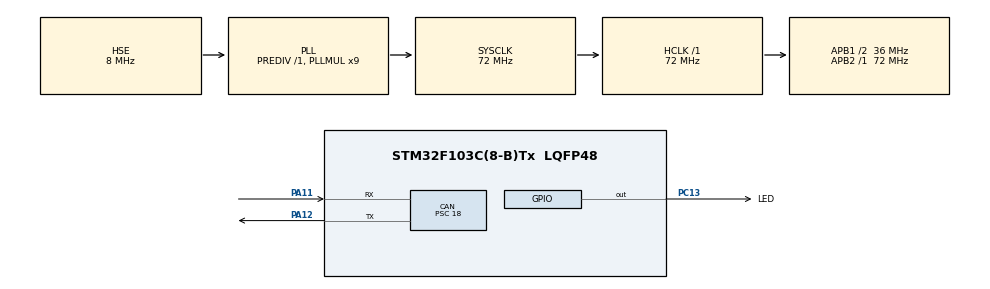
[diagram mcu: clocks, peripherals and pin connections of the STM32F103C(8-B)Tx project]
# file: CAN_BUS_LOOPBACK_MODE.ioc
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CAN.BS1=CAN_BS1_2TQ
CAN.CalculateBaudRate=500000
CAN.CalculateTimeBit=2000
CAN.CalculateTimeQuantum=500.0
CAN.Mode=CAN_MODE_LOOPBACK
CAN.Prescaler=18
CAN.SJW=CAN_SJW_1TQ
Mcu.Family=STM32F1
Mcu.Name=STM32F103C(8-B)Tx
Mcu.Package=LQFP48
NVIC.CAN1_RX1_IRQn=true\:0\:0\:false\:false\:true\:true\:true
NVIC.PriorityGroup=NVIC_PRIORITYGROUP_4
NVIC.USB_LP_CAN1_RX0_IRQn=true\:0\:0\:true\:false\:true\:true\:true
PA11.Mode=CAN_Activate
PA11.Signal=CAN_RX
PA12.Mode=CAN_Activate
PA12.Signal=CAN_TX
PA13.Mode=Serial_Wire
PA13.Signal=SYS_JTMS-SWDIO
PA14.Mode=Serial_Wire
PA14.Signal=SYS_JTCK-SWCLK
PC13-TAMPER-RTC.GPIO_Label=LED
PC13-TAMPER-RTC.PinState=GPIO_PIN_SET
PC13-TAMPER-RTC.Signal=GPIO_Output
PD0-OSC_IN.Mode=HSE-External-Oscillator
PD0-OSC_IN.Signal=RCC_OSC_IN
PD1-OSC_OUT.Mode=HSE-External-Oscillator
PD1-OSC_OUT.Signal=RCC_OSC_OUT
ProjectManager.HeapSize=0x200
ProjectManager.StackSize=0x400
ProjectManager.TargetToolchain=STM32CubeIDE
RCC.AHBFreq_Value=72000000
RCC.APB1CLKDivider=RCC_HCLK_DIV2
RCC.APB1Freq_Value=36000000
RCC.APB1TimFreq_Value=72000000
RCC.APB2Freq_Value=72000000
RCC.APB2TimFreq_Value=72000000
RCC.HCLKFreq_Value=72000000
RCC.PLLMUL=RCC_PLL_MUL9
RCC.PLLSourceVirtual=RCC_PLLSOURCE_HSE
RCC.SYSCLKFreq_VALUE=72000000
RCC.SYSCLKSource=RCC_SYSCLKSOURCE_PLLCLK
RCC.USBFreq_Value=72000000
board=custom

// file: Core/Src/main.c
/* USER CODE BEGIN Header */
/**
  ******************************************************************************
  * @file           : main.c
  * @brief          : Main program body
  ******************************************************************************
  * @attention
  *
  * Copyright (c) 2022 STMicroelectronics.
  * All rights reserved.
  *
  * This software is licensed under terms that can be found in the LICENSE file
  * in the root directory of this software component.
  * If no LICENSE file comes with this software, it is provided AS-IS.
  *
  ******************************************************************************
  */
/* USER CODE END Header */
#include "main.h"

CAN_HandleTypeDef hcan;

/* USER CODE BEGIN PV */
CAN_TxHeaderTypeDef TxHeader;
CAN_RxHeaderTypeDef RxHeader;

uint8_t				TxData[8];
uint8_t				RxData[8];

uint32_t			TxMailbox[4];
uint8_t				count = 0;

uint32_t			last_time = 0;
/* USER CODE END PV */

void SystemClock_Config(void);
static void MX_GPIO_Init(void);
static void MX_CAN_Init(void);

/* USER CODE BEGIN 0 */
void HAL_CAN_RxFifo0MsgPendingCallback(CAN_HandleTypeDef *hcan)
{
	HAL_CAN_GetRxMessage(hcan, CAN_RX_FIFO0, &RxHeader, RxData);
	//HAL_GPIO_TogglePin(GPIOC, GPIO_PIN_13);
	count++;
}

void HAL_GPIO_EXTI_Callback(uint16_t GPIO_PIN)
{
	/*
	if (GPIO_PIN == GPIO_PIN_0)
	{
		if (HAL_GetTick() - last_time >= 200)
		{
			last_time = HAL_GetTick();
			count++;
			TxData[0] = count;
			HAL_CAN_AddTxMessage(&hcan, &TxHeader, TxData, &TxMailbox);
		}

	}
	*/
}

/* USER CODE END 0 */

int main(void)
{

  /* MCU Configuration--------------------------------------------------------*/

  /* Reset of all peripherals, Initializes the Flash interface and the Systick. */
  HAL_Init();

  /* Configure the system clock */
  SystemClock_Config();

  /* Initialize all configured peripherals */
  MX_GPIO_Init();
  MX_CAN_Init();
  /* USER CODE BEGIN 2 */

  HAL_CAN_Start(&hcan);

  HAL_CAN_ActivateNotification(&hcan, CAN_IT_RX_FIFO0_MSG_PENDING);

  TxHeader.DLC = 1; // Data length in byte
  TxHeader.ExtId = 0; //Using standard id
  TxHeader.IDE = CAN_ID_STD; // Standard ID
  TxHeader.RTR = CAN_RTR_DATA; //Sending Data frame instead of remote frame
  TxHeader.StdId = 0x103;
  TxHeader.TransmitGlobalTime = DISABLE;

  TxData[0] = 1;
  TxData[1] = 2;
  TxData[2] = 3;
  TxData[3] = 4;

  if (HAL_CAN_AddTxMessage(&hcan, &TxHeader, &TxData[0], &TxMailbox[0]) != HAL_OK)
  {
	  Error_Handler();
  }
  if (HAL_CAN_AddTxMessage(&hcan, &TxHeader, &TxData[1], &TxMailbox[1]) != HAL_OK)
	{
	  Error_Handler();
	}
  if (HAL_CAN_AddTxMessage(&hcan, &TxHeader, &TxData[2], &TxMailbox[2]) != HAL_OK)
  {
	  Error_Handler();
  }

  /* USER CODE END 2 */

  /* Infinite loop */
  /* USER CODE BEGIN WHILE */
  while (1)
  {

	//count++;
	//TxData[0] = count;
	//HAL_CAN_AddTxMessage(&hcan, &TxHeader, TxData, &TxMailbox);
	//HAL_Delay(1000);

    /* USER CODE END WHILE */

  }
}

void SystemClock_Config(void)
{
  RCC_OscInitTypeDef RCC_OscInitStruct = {0};
  RCC_ClkInitTypeDef RCC_ClkInitStruct = {0};

  /** Initializes the RCC Oscillators according to the specified parameters
  * in the RCC_OscInitTypeDef structure.
  */
  RCC_OscInitStruct.OscillatorType = RCC_OSCILLATORTYPE_HSE;
  RCC_OscInitStruct.HSEState = RCC_HSE_ON;
  RCC_OscInitStruct.HSEPredivValue = RCC_HSE_PREDIV_DIV1;
  RCC_OscInitStruct.HSIState = RCC_HSI_ON;
  RCC_OscInitStruct.PLL.PLLState = RCC_PLL_ON;
  RCC_OscInitStruct.PLL.PLLSource = RCC_PLLSOURCE_HSE;
  RCC_OscInitStruct.PLL.PLLMUL = RCC_PLL_MUL9;
  if (HAL_RCC_OscConfig(&RCC_OscInitStruct) != HAL_OK)
  {
    Error_Handler();
  }
  /** Initializes the CPU, AHB and APB buses clocks
  */
  RCC_ClkInitStruct.ClockType = RCC_CLOCKTYPE_HCLK|RCC_CLOCKTYPE_SYSCLK
                              |RCC_CLOCKTYPE_PCLK1|RCC_CLOCKTYPE_PCLK2;
  RCC_ClkInitStruct.SYSCLKSource = RCC_SYSCLKSOURCE_PLLCLK;
  RCC_ClkInitStruct.AHBCLKDivider = RCC_SYSCLK_DIV1;
  RCC_ClkInitStruct.APB1CLKDivider = RCC_HCLK_DIV2;
  RCC_ClkInitStruct.APB2CLKDivider = RCC_HCLK_DIV1;

  if (HAL_RCC_ClockConfig(&RCC_ClkInitStruct, FLASH_LATENCY_2) != HAL_OK)
  {
    Error_Handler();
  }
}

static void MX_CAN_Init(void)
{

  hcan.Instance = CAN1;
  hcan.Init.Prescaler = 18;
  hcan.Init.Mode = CAN_MODE_LOOPBACK;
  hcan.Init.SyncJumpWidth = CAN_SJW_1TQ;
  hcan.Init.TimeSeg1 = CAN_BS1_2TQ;
  hcan.Init.TimeSeg2 = CAN_BS2_1TQ;
  hcan.Init.TimeTriggeredMode = DISABLE;
  hcan.Init.AutoBusOff = DISABLE;
  hcan.Init.AutoWakeUp = DISABLE;
  hcan.Init.AutoRetransmission = DISABLE;
  hcan.Init.ReceiveFifoLocked = DISABLE;
  hcan.Init.TransmitFifoPriority = DISABLE;
  if (HAL_CAN_Init(&hcan) != HAL_OK)
  {
    Error_Handler();
  }
  /* USER CODE BEGIN CAN_Init 2 */
  CAN_FilterTypeDef canfilterconfig;
  canfilterconfig.FilterActivation = CAN_FILTER_ENABLE;
  canfilterconfig.FilterBank = 10; //anything between 0 to SlaveStartFilterBank
  canfilterconfig.FilterFIFOAssignment = CAN_RX_FIFO0;
  canfilterconfig.FilterIdHigh = 0x102<<5;
  canfilterconfig.FilterIdLow = 0x0000;
  canfilterconfig.FilterMaskIdHigh = 0x102<<5;
  canfilterconfig.FilterMaskIdLow = 0x0000;
  canfilterconfig.FilterMode = CAN_FILTERMODE_IDMASK;
  canfilterconfig.FilterScale = CAN_FILTERSCALE_32BIT;
  canfilterconfig.SlaveStartFilterBank = 13; // if only 1 CAN BUS, this parameter is useless

  HAL_CAN_ConfigFilter(&hcan, &canfilterconfig);

  /* USER CODE END CAN_Init 2 */

}

static void MX_GPIO_Init(void)
{
  GPIO_InitTypeDef GPIO_InitStruct = {0};

  /* GPIO Ports Clock Enable */
  __HAL_RCC_GPIOC_CLK_ENABLE();
  __HAL_RCC_GPIOD_CLK_ENABLE();
  __HAL_RCC_GPIOA_CLK_ENABLE();

  /*Configure GPIO pin Output Level */
  HAL_GPIO_WritePin(LED_GPIO_Port, LED_Pin, GPIO_PIN_SET);

  /*Configure GPIO pin : LED_Pin */
  GPIO_InitStruct.Pin = LED_Pin;
  GPIO_InitStruct.Mode = GPIO_MODE_OUTPUT_PP;
  GPIO_InitStruct.Pull = GPIO_NOPULL;
  GPIO_InitStruct.Speed = GPIO_SPEED_FREQ_LOW;
  HAL_GPIO_Init(LED_GPIO_Port, &GPIO_InitStruct);

}

void Error_Handler(void)
{
  __disable_irq();
  while (1)
  {
  }
}
